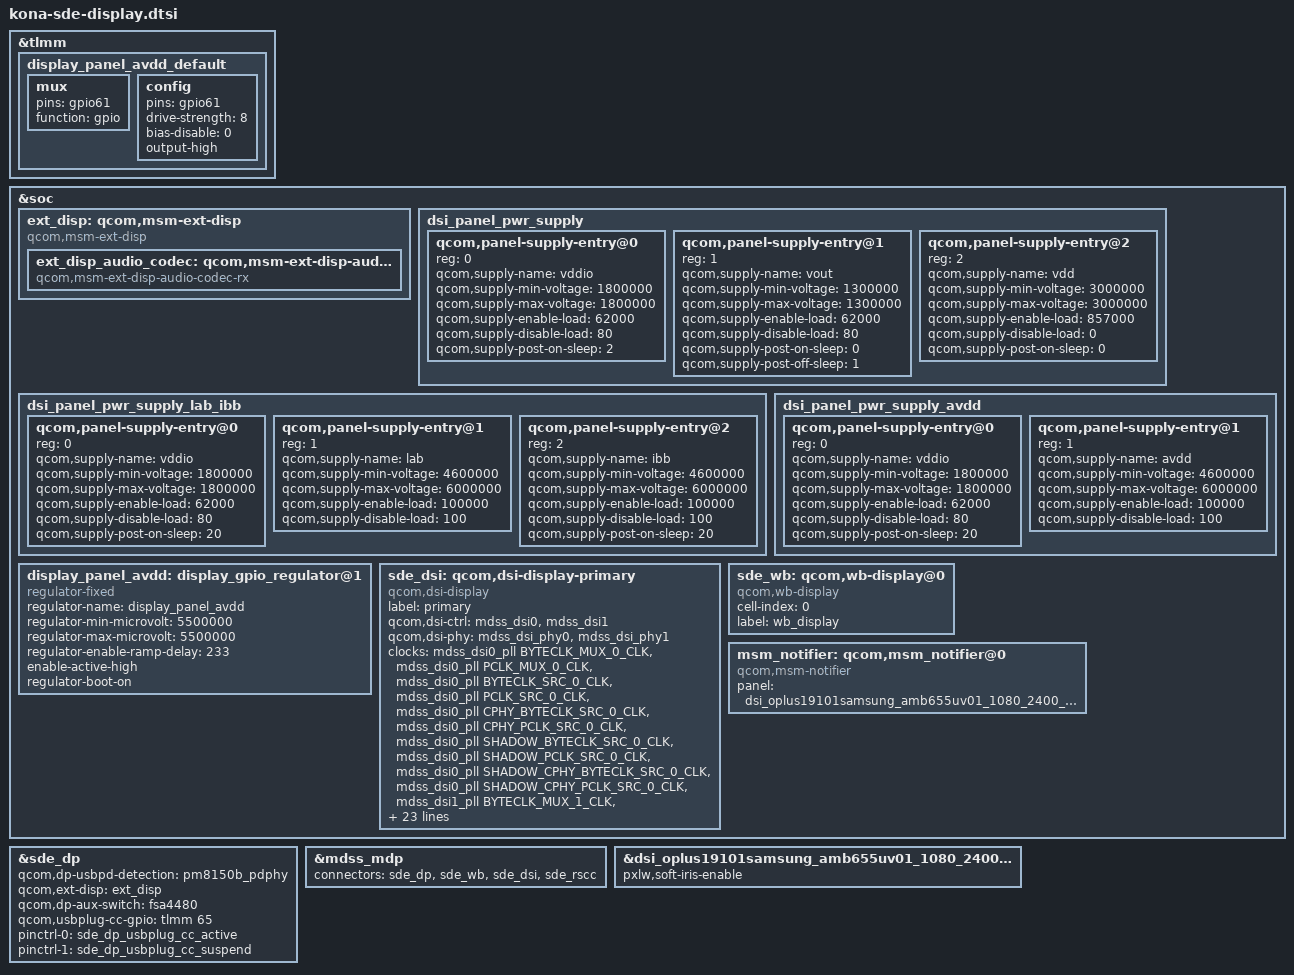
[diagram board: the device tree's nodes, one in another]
#include "dsi-panel-oplus19101samsung-amb655uv01-1080-2400-90fps.dtsi"
#include <dt-bindings/clock/mdss-7nm-pll-clk.h>

&tlmm {
	display_panel_avdd_default: display_panel_avdd_default {
		mux {
			pins = "gpio61";
			function = "gpio";
		};

		config {
			pins = "gpio61";
			drive-strength = <8>;
			bias-disable = <0>;
			output-high;
		};
	};
};

&soc {
	ext_disp: qcom,msm-ext-disp {
		compatible = "qcom,msm-ext-disp";

		ext_disp_audio_codec: qcom,msm-ext-disp-audio-codec-rx {
			compatible = "qcom,msm-ext-disp-audio-codec-rx";
		};
	};

	dsi_panel_pwr_supply: dsi_panel_pwr_supply {
		#address-cells = <1>;
		#size-cells = <0>;

		qcom,panel-supply-entry@0 {
			reg = <0>;
			qcom,supply-name = "vddio";
			qcom,supply-min-voltage = <1800000>;
			qcom,supply-max-voltage = <1800000>;
			qcom,supply-enable-load = <62000>;
			qcom,supply-disable-load = <80>;
			qcom,supply-post-on-sleep = <2>;
		};

		qcom,panel-supply-entry@1 {
			reg = <1>;
			qcom,supply-name = "vout";
			qcom,supply-min-voltage = <1300000>;
			qcom,supply-max-voltage = <1300000>;
			qcom,supply-enable-load = <62000>;
			qcom,supply-disable-load = <80>;
			qcom,supply-post-on-sleep = <0>;
			qcom,supply-post-off-sleep = <1>;
		};

		qcom,panel-supply-entry@2 {
			reg = <2>;
			qcom,supply-name = "vdd";
			qcom,supply-min-voltage = <3000000>;
			qcom,supply-max-voltage = <3000000>;
			qcom,supply-enable-load = <857000>;
			qcom,supply-disable-load = <0>;
			qcom,supply-post-on-sleep = <0>;
		};
	};
       //#endif
	dsi_panel_pwr_supply_lab_ibb: dsi_panel_pwr_supply_lab_ibb {
		#address-cells = <1>;
		#size-cells = <0>;

		qcom,panel-supply-entry@0 {
			reg = <0>;
			qcom,supply-name = "vddio";
			qcom,supply-min-voltage = <1800000>;
			qcom,supply-max-voltage = <1800000>;
			qcom,supply-enable-load = <62000>;
			qcom,supply-disable-load = <80>;
			qcom,supply-post-on-sleep = <20>;
		};

		qcom,panel-supply-entry@1 {
			reg = <1>;
			qcom,supply-name = "lab";
			qcom,supply-min-voltage = <4600000>;
			qcom,supply-max-voltage = <6000000>;
			qcom,supply-enable-load = <100000>;
			qcom,supply-disable-load = <100>;
		};

		qcom,panel-supply-entry@2 {
			reg = <2>;
			qcom,supply-name = "ibb";
			qcom,supply-min-voltage = <4600000>;
			qcom,supply-max-voltage = <6000000>;
			qcom,supply-enable-load = <100000>;
			qcom,supply-disable-load = <100>;
			qcom,supply-post-on-sleep = <20>;
		};
	};

	dsi_panel_pwr_supply_avdd: dsi_panel_pwr_supply_avdd {
		#address-cells = <1>;
		#size-cells = <0>;

		qcom,panel-supply-entry@0 {
			reg = <0>;
			qcom,supply-name = "vddio";
			qcom,supply-min-voltage = <1800000>;
			qcom,supply-max-voltage = <1800000>;
			qcom,supply-enable-load = <62000>;
			qcom,supply-disable-load = <80>;
			qcom,supply-post-on-sleep = <20>;
		};

		qcom,panel-supply-entry@1 {
			reg = <1>;
			qcom,supply-name = "avdd";
			qcom,supply-min-voltage = <4600000>;
			qcom,supply-max-voltage = <6000000>;
			qcom,supply-enable-load = <100000>;
			qcom,supply-disable-load = <100>;
		};
	};

	display_panel_avdd: display_gpio_regulator@1 {
		compatible = "regulator-fixed";
		regulator-name = "display_panel_avdd";
		regulator-min-microvolt = <5500000>;
		regulator-max-microvolt = <5500000>;
		regulator-enable-ramp-delay = <233>;
		//#ifndef OPLUS_FEATURE_CHG_BASIC//huangtongfeng@ProDrv.CHG,add 2019/06/21 for vib aw8697
		//gpio = <&tlmm 61 0>;
		//#endif
		enable-active-high;
		regulator-boot-on;
		//#ifndef OPLUS_FEATURE_CHG_BASIC//huangtongfeng@ProDrv.CHG,add 2019/06/21 for vib aw8697
		//pinctrl-names = "default";
		//pinctrl-0 = <&display_panel_avdd_default>;
		//#endif
	};

	sde_dsi: qcom,dsi-display-primary {
		compatible = "qcom,dsi-display";
		label = "primary";

		qcom,dsi-ctrl = <&mdss_dsi0 &mdss_dsi1>;
		qcom,dsi-phy = <&mdss_dsi_phy0 &mdss_dsi_phy1>;

		clocks = <&mdss_dsi0_pll BYTECLK_MUX_0_CLK>,
			 <&mdss_dsi0_pll PCLK_MUX_0_CLK>,
			 <&mdss_dsi0_pll BYTECLK_SRC_0_CLK>,
			 <&mdss_dsi0_pll PCLK_SRC_0_CLK>,
			 <&mdss_dsi0_pll CPHY_BYTECLK_SRC_0_CLK>,
			 <&mdss_dsi0_pll CPHY_PCLK_SRC_0_CLK>,
			 <&mdss_dsi0_pll SHADOW_BYTECLK_SRC_0_CLK>,
			 <&mdss_dsi0_pll SHADOW_PCLK_SRC_0_CLK>,
			 <&mdss_dsi0_pll SHADOW_CPHY_BYTECLK_SRC_0_CLK>,
			 <&mdss_dsi0_pll SHADOW_CPHY_PCLK_SRC_0_CLK>,
			 <&mdss_dsi1_pll BYTECLK_MUX_1_CLK>,
			 <&mdss_dsi1_pll PCLK_MUX_1_CLK>,
			 <&mdss_dsi1_pll BYTECLK_SRC_1_CLK>,
			 <&mdss_dsi1_pll PCLK_SRC_1_CLK>,
			 <&mdss_dsi1_pll CPHY_BYTECLK_SRC_1_CLK>,
			 <&mdss_dsi1_pll CPHY_PCLK_SRC_1_CLK>,
			 <&mdss_dsi1_pll SHADOW_BYTECLK_SRC_1_CLK>,
			 <&mdss_dsi1_pll SHADOW_PCLK_SRC_1_CLK>,
			 <&mdss_dsi1_pll SHADOW_CPHY_BYTECLK_SRC_1_CLK>,
			 <&mdss_dsi1_pll SHADOW_CPHY_PCLK_SRC_1_CLK>,
			 <&clock_rpmh RPMH_LN_BB_CLK2>;

			 /* #if defined(CONFIG_PXLW_IRIS5) */
			 /*TODO: <&rpmhcc RPMH_LN_BB_CLK2>;*/
			 /* #endif */

		clock-names = "mux_byte_clk0", "mux_pixel_clk0",
				"src_byte_clk0", "src_pixel_clk0",
				"cphy_byte_clk0", "cphy_pixel_clk0",
				"shadow_byte_clk0", "shadow_pixel_clk0",
				"shadow_cphybyte_clk0", "shadow_cphypixel_clk0",
				"mux_byte_clk1", "mux_pixel_clk1",
				"src_byte_clk1", "src_pixel_clk1",
				"cphy_byte_clk1", "cphy_pixel_clk1",
				"shadow_byte_clk1", "shadow_pixel_clk1",
				"shadow_cphybyte_clk1", "shadow_cphypixel_clk1",
				"pw_bb_clk2";
				/* #if defined(CONFIG_PXLW_IRIS5) */
				/*TODO: "ln_bb_clk2"*/
				/* #endif */

		pinctrl-names = "panel_active", "panel_suspend";
		/* #if defined(CONFIG_PXLW_IRIS5) */
		pinctrl-0 = <&sde_dsi_active &panel_vout_active &sde_te_active>;
		pinctrl-1 = <&sde_dsi_suspend &panel_vout_suspend &sde_te_suspend>;
		/* #endif */

		qcom,platform-te-gpio = <&tlmm 66 0>;
		qcom,panel-te-source = <0>;

		vddio-supply = <&pm8150_l14>;
		vdd-supply = <&pm8150a_l11>;
		vout-supply = <&L2C>;
		avdd-supply = <&display_panel_avdd>;
		//#ifdef VENDOR_EDIT
		qcom,mdp = <&mdss_mdp>;
		qcom,dsi-default-panel = <&dsi_oplus19101samsung_amb655uv01_1080_2400_cmd>;
		//#endif
	};

	sde_wb: qcom,wb-display@0 {
		compatible = "qcom,wb-display";
		cell-index = <0>;
		label = "wb_display";
	};

	msm_notifier: qcom,msm_notifier@0 {
		compatible = "qcom,msm-notifier";
		panel = <&dsi_oplus19101samsung_amb655uv01_1080_2400_cmd>;
	};
        //#endif
};

&sde_dp {
	qcom,dp-usbpd-detection = <&pm8150b_pdphy>;
	qcom,ext-disp = <&ext_disp>;
	qcom,dp-aux-switch = <&fsa4480>;

	qcom,usbplug-cc-gpio = <&tlmm 65 0>;

	pinctrl-names = "mdss_dp_active", "mdss_dp_sleep";
	pinctrl-0 = <&sde_dp_usbplug_cc_active>;
	pinctrl-1 = <&sde_dp_usbplug_cc_suspend>;
};

&mdss_mdp {
	connectors = <&sde_dp &sde_wb &sde_dsi &sde_rscc>;
};

&dsi_oplus19101samsung_amb655uv01_1080_2400_cmd {
    pxlw,soft-iris-enable;
};
